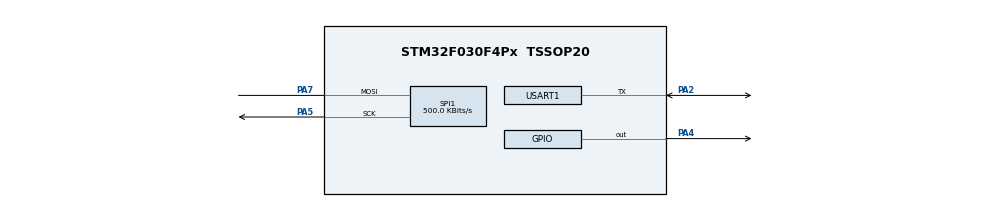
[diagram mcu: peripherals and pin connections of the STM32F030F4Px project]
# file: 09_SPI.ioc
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Mcu.Family=STM32F0
Mcu.Name=STM32F030F4Px
Mcu.Package=TSSOP20
PA13.Mode=Serial_Wire
PA13.Signal=SYS_SWDIO
PA14.Mode=Serial_Wire
PA14.Signal=SYS_SWCLK
PA2.Mode=Half_duplex(single_wire_mode)
PA2.Signal=USART1_TX
PA4.Signal=GPIO_Output
PA5.Mode=Simplex_Bidirectional_Master
PA5.Signal=SPI1_SCK
PA7.Mode=Simplex_Bidirectional_Master
PA7.Signal=SPI1_MOSI
ProjectManager.HeapSize=0x200
ProjectManager.StackSize=0x400
ProjectManager.TargetToolchain=TrueSTUDIO
SPI1.BaudRatePrescaler=SPI_BAUDRATEPRESCALER_16
SPI1.CalculateBaudRate=500.0 KBits/s
SPI1.DataSize=SPI_DATASIZE_8BIT
SPI1.Direction=SPI_DIRECTION_1LINE
SPI1.Mode=SPI_MODE_MASTER
SPI1.VirtualType=VM_MASTER
USART1.VirtualMode-Half_duplex(single_wire_mode)=VM_ASYNC
board=09_SPI

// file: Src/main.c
/**
  ******************************************************************************
  * File Name          : main.c
  * Description        : Main program body
  ******************************************************************************
  ** This notice applies to any and all portions of this file
  * that are not between comment pairs USER CODE BEGIN and
  * USER CODE END. Other portions of this file, whether
  * inserted by the user or by software development tools
  * are owned by their respective copyright owners.
  *
  * COPYRIGHT(c) 2018 STMicroelectronics
  *
  * Redistribution and use in source and binary forms, with or without modification,
  * are permitted provided that the following conditions are met:
  *   1. Redistributions of source code must retain the above copyright notice,
  *      this list of conditions and the following disclaimer.
  *   2. Redistributions in binary form must reproduce the above copyright notice,
  *      this list of conditions and the following disclaimer in the documentation
  *      and/or other materials provided with the distribution.
  *   3. Neither the name of STMicroelectronics nor the names of its contributors
  *      may be used to endorse or promote products derived from this software
  *      without specific prior written permission.
  *
  * THIS SOFTWARE IS PROVIDED BY THE COPYRIGHT HOLDERS AND CONTRIBUTORS "AS IS"
  * AND ANY EXPRESS OR IMPLIED WARRANTIES, INCLUDING, BUT NOT LIMITED TO, THE
  * IMPLIED WARRANTIES OF MERCHANTABILITY AND FITNESS FOR A PARTICULAR PURPOSE ARE
  * DISCLAIMED. IN NO EVENT SHALL THE COPYRIGHT HOLDER OR CONTRIBUTORS BE LIABLE
  * FOR ANY DIRECT, INDIRECT, INCIDENTAL, SPECIAL, EXEMPLARY, OR CONSEQUENTIAL
  * DAMAGES (INCLUDING, BUT NOT LIMITED TO, PROCUREMENT OF SUBSTITUTE GOODS OR
  * SERVICES; LOSS OF USE, DATA, OR PROFITS; OR BUSINESS INTERRUPTION) HOWEVER
  * CAUSED AND ON ANY THEORY OF LIABILITY, WHETHER IN CONTRACT, STRICT LIABILITY,
  * OR TORT (INCLUDING NEGLIGENCE OR OTHERWISE) ARISING IN ANY WAY OUT OF THE USE
  * OF THIS SOFTWARE, EVEN IF ADVISED OF THE POSSIBILITY OF SUCH DAMAGE.
  *
  ******************************************************************************
  */
#include "main.h"
#include "stm32f0xx_hal.h"

SPI_HandleTypeDef hspi1;

UART_HandleTypeDef huart1;

/* USER CODE BEGIN PV */
/* Private variables ---------------------------------------------------------*/

/* USER CODE END PV */

void SystemClock_Config(void);
static void MX_GPIO_Init(void);
static void MX_SPI1_Init(void);
static void MX_USART1_UART_Init(void);

/* USER CODE BEGIN PFP */
/* Private function prototypes -----------------------------------------------*/
void digiPot_Write(int i);
/* USER CODE END PFP */

int main(void)
{

  /* MCU Configuration----------------------------------------------------------*/

  /* Reset of all peripherals, Initializes the Flash interface and the Systick. */
  HAL_Init();

  /* Configure the system clock */
  SystemClock_Config();

  /* Initialize all configured peripherals */
  MX_GPIO_Init();
  MX_SPI1_Init();
  MX_USART1_UART_Init();

  /* USER CODE BEGIN 2 */

  // enable the SPI module
   __HAL_SPI_ENABLE(&hspi1);

  /* USER CODE END 2 */

  /* Infinite loop */
  while (1)
  {

  /* USER CODE BEGIN 3 */

	  // seven bit resolution
	  for(int i = 0; i<= 127; i++)
	  {
		  // write value to digipot
		  digiPot_Write(i);
		  HAL_Delay(100);
	  }

  }
  /* USER CODE END 3 */

}

/** System Clock Configuration
*/
void SystemClock_Config(void)
{

  RCC_OscInitTypeDef RCC_OscInitStruct;
  RCC_ClkInitTypeDef RCC_ClkInitStruct;
  RCC_PeriphCLKInitTypeDef PeriphClkInit;

    /**Initializes the CPU, AHB and APB busses clocks
    */
  RCC_OscInitStruct.OscillatorType = RCC_OSCILLATORTYPE_HSI;
  RCC_OscInitStruct.HSIState = RCC_HSI_ON;
  RCC_OscInitStruct.HSICalibrationValue = 16;
  RCC_OscInitStruct.PLL.PLLState = RCC_PLL_NONE;
  if (HAL_RCC_OscConfig(&RCC_OscInitStruct) != HAL_OK)
  {
    _Error_Handler(__FILE__, __LINE__);
  }

    /**Initializes the CPU, AHB and APB busses clocks
    */
  RCC_ClkInitStruct.ClockType = RCC_CLOCKTYPE_HCLK|RCC_CLOCKTYPE_SYSCLK
                              |RCC_CLOCKTYPE_PCLK1;
  RCC_ClkInitStruct.SYSCLKSource = RCC_SYSCLKSOURCE_HSI;
  RCC_ClkInitStruct.AHBCLKDivider = RCC_SYSCLK_DIV1;
  RCC_ClkInitStruct.APB1CLKDivider = RCC_HCLK_DIV1;

  if (HAL_RCC_ClockConfig(&RCC_ClkInitStruct, FLASH_LATENCY_0) != HAL_OK)
  {
    _Error_Handler(__FILE__, __LINE__);
  }

  PeriphClkInit.PeriphClockSelection = RCC_PERIPHCLK_USART1;
  PeriphClkInit.Usart1ClockSelection = RCC_USART1CLKSOURCE_PCLK1;
  if (HAL_RCCEx_PeriphCLKConfig(&PeriphClkInit) != HAL_OK)
  {
    _Error_Handler(__FILE__, __LINE__);
  }

    /**Configure the Systick interrupt time
    */
  HAL_SYSTICK_Config(HAL_RCC_GetHCLKFreq()/1000);

    /**Configure the Systick
    */
  HAL_SYSTICK_CLKSourceConfig(SYSTICK_CLKSOURCE_HCLK);

  /* SysTick_IRQn interrupt configuration */
  HAL_NVIC_SetPriority(SysTick_IRQn, 0, 0);
}

/* SPI1 init function */
static void MX_SPI1_Init(void)
{

  hspi1.Instance = SPI1;
  hspi1.Init.Mode = SPI_MODE_MASTER;
  hspi1.Init.Direction = SPI_DIRECTION_1LINE;
  hspi1.Init.DataSize = SPI_DATASIZE_8BIT;
  hspi1.Init.CLKPolarity = SPI_POLARITY_LOW;
  hspi1.Init.CLKPhase = SPI_PHASE_1EDGE;
  hspi1.Init.NSS = SPI_NSS_SOFT;
  hspi1.Init.BaudRatePrescaler = SPI_BAUDRATEPRESCALER_16;
  hspi1.Init.FirstBit = SPI_FIRSTBIT_MSB;
  hspi1.Init.TIMode = SPI_TIMODE_DISABLE;
  hspi1.Init.CRCCalculation = SPI_CRCCALCULATION_DISABLE;
  hspi1.Init.CRCPolynomial = 7;
  hspi1.Init.CRCLength = SPI_CRC_LENGTH_DATASIZE;
  hspi1.Init.NSSPMode = SPI_NSS_PULSE_ENABLE;
  if (HAL_SPI_Init(&hspi1) != HAL_OK)
  {
    _Error_Handler(__FILE__, __LINE__);
  }

}

/* USART1 init function */
static void MX_USART1_UART_Init(void)
{

  huart1.Instance = USART1;
  huart1.Init.BaudRate = 38400;
  huart1.Init.WordLength = UART_WORDLENGTH_8B;
  huart1.Init.StopBits = UART_STOPBITS_1;
  huart1.Init.Parity = UART_PARITY_NONE;
  huart1.Init.Mode = UART_MODE_TX_RX;
  huart1.Init.HwFlowCtl = UART_HWCONTROL_NONE;
  huart1.Init.OverSampling = UART_OVERSAMPLING_16;
  huart1.Init.OneBitSampling = UART_ONE_BIT_SAMPLE_DISABLE;
  huart1.AdvancedInit.AdvFeatureInit = UART_ADVFEATURE_NO_INIT;
  if (HAL_HalfDuplex_Init(&huart1) != HAL_OK)
  {
    _Error_Handler(__FILE__, __LINE__);
  }

}

/** Configure pins as
        * Analog
        * Input
        * Output
        * EVENT_OUT
        * EXTI
*/
static void MX_GPIO_Init(void)
{

  GPIO_InitTypeDef GPIO_InitStruct;

  /* GPIO Ports Clock Enable */
  __HAL_RCC_GPIOA_CLK_ENABLE();

  /*Configure GPIO pin Output Level */
  HAL_GPIO_WritePin(GPIOA, GPIO_PIN_4, GPIO_PIN_RESET);

  /*Configure GPIO pin : PA4 */
  GPIO_InitStruct.Pin = GPIO_PIN_4;
  GPIO_InitStruct.Mode = GPIO_MODE_OUTPUT_PP;
  GPIO_InitStruct.Pull = GPIO_NOPULL;
  GPIO_InitStruct.Speed = GPIO_SPEED_FREQ_LOW;
  HAL_GPIO_Init(GPIOA, &GPIO_InitStruct);

}

/* USER CODE BEGIN 4 */

/*******************************************************************************
 * Function: digiPot_Write
 *
 * Returns: Nothing
 *
 * Description: Writes a particular value to a MCP4131 digital potentiometer
 *
 * Usage: digiPot_write(i);
 ******************************************************************************/

void digiPot_Write(int i)
{
	 int x = 0x00;

	 HAL_GPIO_WritePin(GPIOA, GPIO_PIN_4, GPIO_PIN_RESET);
	 HAL_SPI_Transmit(&hspi1, (uint8_t*)&x, 0x01, 10);
     HAL_SPI_Transmit(&hspi1, (uint8_t*)&i, 0x01, 10);
     HAL_GPIO_WritePin(GPIOA, GPIO_PIN_4, GPIO_PIN_SET);
}

/* USER CODE END 4 */

void _Error_Handler(char * file, int line)
{
  while(1)
  {
  }
}

/************************ (C) COPYRIGHT STMicroelectronics *****END OF FILE****/
